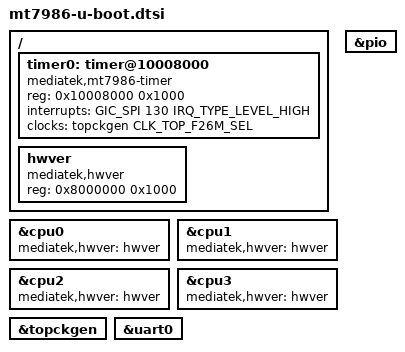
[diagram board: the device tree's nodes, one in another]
// SPDX-License-Identifier: GPL-2.0
/*
 * Copyright (c) 2022 MediaTek Inc.
 * Author: Sam Shih <sam.shih@mediatek.com>
 */

/{
	timer0: timer@10008000 {
		compatible = "mediatek,mt7986-timer";
		reg = <0x10008000 0x1000>;
		interrupts = <GIC_SPI 130 IRQ_TYPE_LEVEL_HIGH>;
		clocks = <&topckgen CLK_TOP_F26M_SEL>;
		clock-names = "gpt-clk";
		bootph-all;
	};

	hwver: hwver {
		compatible = "mediatek,hwver", "syscon";
		reg = <0x8000000 0x1000>;
	};
};

&cpu0 {
	mediatek,hwver = <&hwver>;
};

&cpu1 {
	mediatek,hwver = <&hwver>;
};

&cpu2 {
	mediatek,hwver = <&hwver>;
};

&cpu3 {
	mediatek,hwver = <&hwver>;
};

&topckgen {
	bootph-all;
};

/*&pericfg {
	bootph-all;
};

&apmixedsys {
	bootph-all;
};*/

&uart0 {
	bootph-all;
};

&pio {
	bootph-all;
};
